// Description: LIN Description file created by VFA
// Created: 12 Jan 2022
// Author: Davide Motta
// Version: 1.0
// Note:

LIN_description_file;
LIN_protocol_version = "2.1";
LIN_language_version = "2.1";
LIN_speed = 19.2 kbps;

Nodes {
  Master: BodyControllerModule, 10 ms, 0 ms ;
  Slaves: ACU5425 ;
}

Signals {
  Windows_Status: 1, 0, BodyControllerModule, ACU5425 ;
  DriverDoor: 1, 0, BodyControllerModule, ACU5425 ;
  PassengerDoor: 1, 0, BodyControllerModule, ACU5425 ;
  USS_Arm_Disarm: 1, 0, BodyControllerModule, ACU5425 ;
  FrontServiceHatch: 1, 0, BodyControllerModule, ACU5425 ;
  BMislockNotification: 1, 0, BodyControllerModule, ACU5425 ;
  CargoSideSlidingDoor: 1, 0, BodyControllerModule, ACU5425 ;
  CargoRearDoor: 1, 0, BodyControllerModule, ACU5425 ;
  FanAirConditioned_Status: 1, 0, BodyControllerModule, ACU5425 ;
  Master0_Code: 8, 85, BodyControllerModule, ACU5425 ;
  Master1_Code: 4, 5, BodyControllerModule, ACU5425 ;
  Master1_Msg_Counter: 4, 5, BodyControllerModule, ACU5425 ;
  MW_Arm_Disarm: 2, 0, BodyControllerModule, ACU5425 ;
  MW_status: 1, 0, ACU5425, BodyControllerModule ;
  USSBankSelection: 4, 0, BodyControllerModule, ACU5425 ;
  Reserved00: 1, 0, BodyControllerModule, ACU5425 ;
  Reserved02: 4, 0, BodyControllerModule, ACU5425 ;
  Reserved01: 3, 0, BodyControllerModule, ACU5425 ;
  Reserved03: 2, 0, BodyControllerModule, ACU5425 ;
  Reserved05: 3, 0, ACU5425, BodyControllerModule ;
  Reserved06: 3, 0, ACU5425, BodyControllerModule ;
  Reserved07: 1, 0, ACU5425, BodyControllerModule ;
  Reserved08: 1, 0, ACU5425, BodyControllerModule ;
  Reserved09: 1, 0, BodyControllerModule, ACU5425 ;
  Reserved10: 1, 0, ACU5425, BodyControllerModule ;
  Reserved11: 1, 0, BodyControllerModule, ACU5425 ;
  PanicAlarm_command: 1, 0, BodyControllerModule, ACU5425 ;
  ACU_LIN_Err: 1, 0, ACU5425, BodyControllerModule ;
  ACU_Active: 1, 0, ACU5425, BodyControllerModule ;
  ACU_Alarm: 1, 0, ACU5425, BodyControllerModule ;
  ACU_alarm_response: 1, 0, BodyControllerModule, ACU5425 ;
  ACU_Arm_Disarm: 1, 0, BodyControllerModule, ACU5425 ;
  ACU_Msg_Counter: 4, 0, ACU5425, BodyControllerModule ;
  ACU_Status: 1, 0, ACU5425, BodyControllerModule ;
  ACU_undervoltage: 1, 0, ACU5425, BodyControllerModule ;
  Tilt_Arm_Disarm: 2, 0, BodyControllerModule, ACU5425 ;
  Tilt_status: 1, 0, ACU5425, BodyControllerModule ;
  ACU_err: 1, 0, ACU5425, BodyControllerModule ;
  Siren_err: 1, 0, ACU5425, BodyControllerModule ;
  MW1_err: 1, 0, ACU5425, BodyControllerModule ;
  MW2_err: 1, 0, ACU5425, BodyControllerModule ;
  Siren_com_err: 1, 0, ACU5425, BodyControllerModule ;
  MW1_com_err: 1, 0, ACU5425, BodyControllerModule ;
  MW2_com_err: 1, 0, ACU5425, BodyControllerModule ;
  Self_test_status: 1, 0, ACU5425, BodyControllerModule ;
  DriverDoor_Alarm: 1, 0, ACU5425, BodyControllerModule ;
  CargoSideSlidingDoor_Alarm: 1, 0, ACU5425, BodyControllerModule ;
  CargoRearDoor_Alarm: 1, 0, ACU5425, BodyControllerModule ;
  FrontServiceHatch_Alarm: 1, 0, ACU5425, BodyControllerModule ;
  PassengerDoor_Alarm: 1, 0, ACU5425, BodyControllerModule ;
  MW2_alarm: 1, 0, ACU5425, BodyControllerModule ;
  MW1_alarm: 1, 0, ACU5425, BodyControllerModule ;
  Siren_pwr_tamper: 1, 0, ACU5425, BodyControllerModule ;
  Siren_com_tamper: 1, 0, ACU5425, BodyControllerModule ;
  USS_status: 2, 0, ACU5425, BodyControllerModule ;
  Tilt_alarm: 1, 0, ACU5425, BodyControllerModule ;
}

Frames {
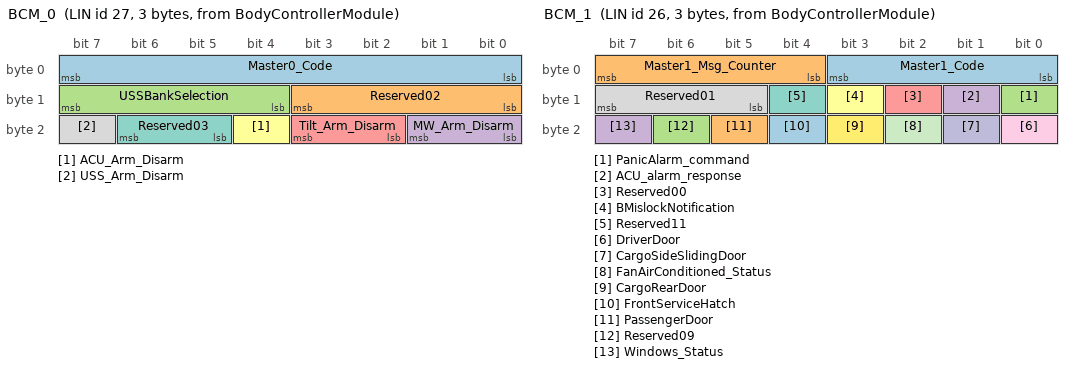
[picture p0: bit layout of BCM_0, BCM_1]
  BCM_0: 27, BodyControllerModule, 3 {
    Master0_Code, 0 ;
    Reserved02, 8 ;
    USSBankSelection, 12 ;
    MW_Arm_Disarm, 16 ;
    Tilt_Arm_Disarm, 18 ;
    ACU_Arm_Disarm, 20 ;
    Reserved03, 21 ;
    USS_Arm_Disarm, 23 ;
  }
  BCM_1: 26, BodyControllerModule, 3 {
    Master1_Code, 0 ;
    Master1_Msg_Counter, 4 ;
    PanicAlarm_command, 8 ;
    ACU_alarm_response, 9 ;
    Reserved00, 10 ;
    BMislockNotification, 11 ;
    Reserved11, 12 ;
    Reserved01, 13 ;
    DriverDoor, 16 ;
    CargoSideSlidingDoor, 17 ;
    FanAirConditioned_Status, 18 ;
    CargoRearDoor, 19 ;
    FrontServiceHatch, 20 ;
    PassengerDoor, 21 ;
    Reserved09, 22 ;
    Windows_Status, 23 ;
  }
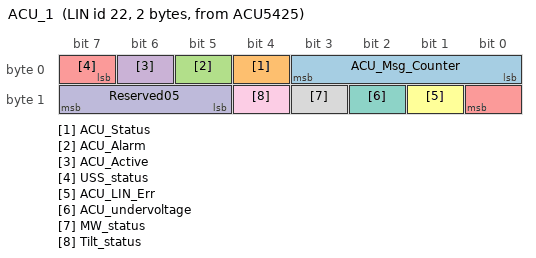
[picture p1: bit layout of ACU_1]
  ACU_1: 22, ACU5425, 2 {
    ACU_Msg_Counter, 0 ;
    ACU_Status, 4 ;
    ACU_Alarm, 5 ;
    ACU_Active, 6 ;
    USS_status, 7 ;
    ACU_LIN_Err, 9 ;
    ACU_undervoltage, 10 ;
    MW_status, 11 ;
    Tilt_status, 12 ;
    Reserved05, 13 ;
  }
  ACU_2: 23, ACU5425, 3 {
    ACU_err, 0 ;
    Siren_err, 1 ;
    MW1_err, 2 ;
    MW2_err, 3 ;
    Siren_com_err, 4 ;
    MW1_com_err, 5 ;
    MW2_com_err, 6 ;
    Self_test_status, 7 ;
    Tilt_alarm, 8 ;
    Siren_pwr_tamper, 9 ;
    Siren_com_tamper, 10 ;
    MW1_alarm, 11 ;
    MW2_alarm, 12 ;
    DriverDoor_Alarm, 13 ;
    CargoSideSlidingDoor_Alarm, 14 ;
    Reserved07, 15 ;
    CargoRearDoor_Alarm, 16 ;
    FrontServiceHatch_Alarm, 17 ;
    PassengerDoor_Alarm, 18 ;
    Reserved10, 19 ;
    Reserved08, 20 ;
    Reserved06, 21 ;
  }
}

Node_attributes {
  ACU5425{
    LIN_protocol = "2.1" ;
    configured_NAD = 0x31 ;
    initial_NAD = 0x31 ;
    product_id = 0x104, 0x0, 0 ;
    response_error = ACU_LIN_Err ;
    P2_min = 50 ms ;
    ST_min = 0 ms ;
    N_As_timeout = 1000 ms ;
    N_Cr_timeout = 1000 ms ;
    configurable_frames {
      ACU_1 ;
      ACU_2 ;
      BCM_0 ;
      BCM_1 ;
    }
  }
}

Schedule_tables {
 LIN_Normal {
    BCM_0 delay 20 ms ;
    BCM_1 delay 20 ms ;
    ACU_1 delay 20 ms ;
    ACU_2 delay 20 ms ;
  }
 LIN_polling {
    BCM_1 delay 20 ms ;
    ACU_1 delay 20 ms ;
  }
 MasterReq_Diag {
    MasterReq delay 20 ms ;
  }
 SlaveResp_Diag {
    SlaveResp delay 20 ms ;
  }
}

Signal_encoding_types {
  Enc_Windows_Status {
    logical_value, 0, "Windows closed" ;
    logical_value, 1, "Windows open" ;
  }
  Enc_DriverDoor {
    logical_value, 0, "Driver door closed" ;
    logical_value, 1, "Driver door open" ;
  }
  Enc_PassengerDoor {
    logical_value, 0, "Passenger door closed" ;
    logical_value, 1, "Passenger door open" ;
  }
  Enc_FrontServiceHatch {
    logical_value, 0, "Front service hatch closed" ;
    logical_value, 1, "Front service hatch open" ;
  }
  Enc_BMislockNotification {
    logical_value, 0, "No mislock detected" ;
    logical_value, 1, "Mislock detected" ;
  }
  Enc_CargoSideSlidingDoor {
    logical_value, 0, "Cargo sliding door closed" ;
    logical_value, 1, "Cargo sliding door open" ;
  }
  Enc_CargoRearDoor {
    logical_value, 0, "Cargo rear door closed" ;
    logical_value, 1, "Cargo rear door open" ;
  }
  Enc_FanAirConditioned_Status {
    logical_value, 0, "Fan or A/C OFF" ;
    logical_value, 1, "Fan or A/C ON" ;
  }
  Enc_USS_Arm_Disarm {
    logical_value, 0, "USS disarm" ;
    logical_value, 1, "USS arm" ;
  }
  Enc_MW_Arm_Disarm {
    logical_value, 0, "MW not present" ;
    logical_value, 1, "MW not present" ;
    logical_value, 2, "MW present / disarm" ;
    logical_value, 3, "MW present / arm" ;
  }
  Enc_MW_status {
    logical_value, 0, "MW disarmed" ;
    logical_value, 1, "MW armed" ;
  }
  Enc_USSBankSelection {
    physical_value, 0, 15, 1, 0, "USS Bank " ;
  }
  Enc_ACU_LIN_Err {
    logical_value, 0, "ACU is operating correctly" ;
    logical_value, 1, "ACU has intermittent problems" ;
  }
  Enc_ACU_Active {
    logical_value, 0, "Sounder OFF" ;
    logical_value, 1, "Sounder ON" ;
  }
  Enc_ACU_Alarm {
    logical_value, 0, "Alarm OFF" ;
    logical_value, 1, "Alarm ON" ;
  }
  Enc_ACU_alarm_response {
    logical_value, 0, "Alarm info NOT ack'd" ;
    logical_value, 1, "Alarm info ack'd" ;
  }
  Enc_ACU_Arm_Disarm {
    logical_value, 0, "ACU disarm" ;
    logical_value, 1, "ACU arm" ;
  }
  Enc_ACU_Status {
    logical_value, 0, "ACU disarmed" ;
    logical_value, 1, "ACU armed" ;
  }
  Enc_ACU_undervoltage {
    logical_value, 0, "Main battery voltage ok" ;
    logical_value, 1, "Main battery voltage low" ;
  }
  Enc_Tilt_Arm_Disarm {
    logical_value, 0, "Tilt present / disarm" ;
    logical_value, 1, "Tilt present / arm" ;
    logical_value, 2, "Extra0" ;
    logical_value, 3, "Extra1" ;
  }
  Enc_Tilt_status {
    logical_value, 0, "Tilt disarmed" ;
    logical_value, 1, "Tilt armed" ;
  }
  Enc_USS_status {
    logical_value, 0, "USS disarmed" ;
    logical_value, 1, "USS armed" ;
  }
  Enc_ACU_err {
    logical_value, 0, "No Error" ;
    logical_value, 1, "Error" ;
  }
  Enc_Siren_Err {
    logical_value, 0, "No Error" ;
    logical_value, 1, "Error" ;
  }
  Enc_MW1_Err {
    logical_value, 0, "No Error" ;
    logical_value, 1, "Error" ;
  }
  Enc_MW2_Err {
    logical_value, 0, "No Error" ;
    logical_value, 1, "Error" ;
  }
  Enc_MW1_COM_Err {
    logical_value, 0, "No Error" ;
    logical_value, 1, "Error" ;
  }
  Enc_MW2_COM_Err {
    logical_value, 0, "No Error" ;
    logical_value, 1, "Error" ;
  }
  Enc_Siren_COM_Err {
    logical_value, 0, "No Error" ;
    logical_value, 1, "Error" ;
  }
  Enc_Self_test_status {
    logical_value, 0, "Self test result available" ;
    logical_value, 1, "Self test in progress" ;
  }
  Enc_Tilt_alarm {
    logical_value, 0, "No Alarm" ;
    logical_value, 1, "Alarm" ;
  }
  Enc_Siren_com_tamper {
    logical_value, 0, "No alarm" ;
    logical_value, 1, "Alarm" ;
  }
  Enc_Siren_pwr_tamper {
    logical_value, 0, "No alarm" ;
    logical_value, 1, "Alarm" ;
  }
  Enc_MW1_alarm {
    logical_value, 0, "No alarm" ;
    logical_value, 1, "Alarm" ;
  }
  Enc_MW2_alarm {
    logical_value, 0, "No alarm" ;
    logical_value, 1, "Alarm" ;
  }
  Enc_Panic_Command {
    logical_value, 0, "Panic mode not active" ;
    logical_value, 1, "Panic mode active" ;
  }
  Enc_ACU_alarm_causes {
    logical_value, 0, "No alarm" ;
    logical_value, 1, "Alarm" ;
  }
}

Signal_representation {
  Enc_ACU_Active: ACU_Active ;
  Enc_ACU_Alarm: ACU_Alarm ;
  Enc_ACU_Arm_Disarm: ACU_Arm_Disarm ;
  Enc_ACU_LIN_Err: ACU_LIN_Err ;
  Enc_ACU_Status: ACU_Status ;
  Enc_ACU_alarm_causes: DriverDoor_Alarm, CargoSideSlidingDoor_Alarm, CargoRearDoor_Alarm, FrontServiceHatch_Alarm, PassengerDoor_Alarm ;
  Enc_ACU_alarm_response: ACU_alarm_response ;
  Enc_ACU_err: ACU_err ;
  Enc_ACU_undervoltage: ACU_undervoltage ;
  Enc_BMislockNotification: BMislockNotification ;
  Enc_CargoRearDoor: CargoRearDoor ;
  Enc_CargoSideSlidingDoor: CargoSideSlidingDoor ;
  Enc_DriverDoor: DriverDoor ;
  Enc_FanAirConditioned_Status: FanAirConditioned_Status ;
  Enc_FrontServiceHatch: FrontServiceHatch ;
  Enc_MW1_COM_Err: MW1_com_err ;
  Enc_MW1_Err: MW1_err ;
  Enc_MW1_alarm: MW1_alarm ;
  Enc_MW2_COM_Err: MW2_com_err ;
  Enc_MW2_Err: MW2_err ;
  Enc_MW2_alarm: MW2_alarm ;
  Enc_MW_Arm_Disarm: MW_Arm_Disarm ;
  Enc_MW_status: MW_status ;
  Enc_Panic_Command: PanicAlarm_command ;
  Enc_PassengerDoor: PassengerDoor ;
  Enc_Self_test_status: Self_test_status ;
  Enc_Siren_COM_Err: Siren_com_err ;
  Enc_Siren_Err: Siren_err ;
  Enc_Siren_com_tamper: Siren_com_tamper ;
  Enc_Siren_pwr_tamper: Siren_pwr_tamper ;
  Enc_Tilt_Arm_Disarm: Tilt_Arm_Disarm ;
  Enc_Tilt_alarm: Tilt_alarm ;
  Enc_Tilt_status: Tilt_status ;
  Enc_USSBankSelection: USSBankSelection ;
  Enc_USS_Arm_Disarm: USS_Arm_Disarm ;
  Enc_USS_status: USS_status ;
  Enc_Windows_Status: Windows_Status ;
}
